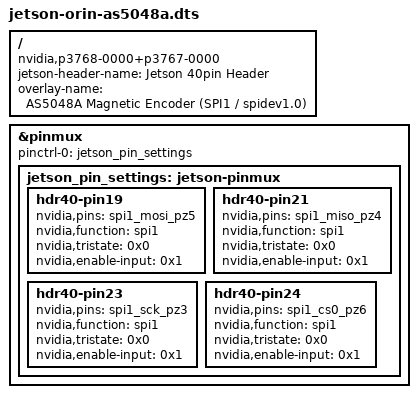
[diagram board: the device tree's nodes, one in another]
/dts-v1/;
/plugin/;

/ {
    jetson-header-name = "Jetson 40pin Header";
    overlay-name = "AS5048A Magnetic Encoder (SPI1 / spidev1.0)";
    compatible = "nvidia,p3768-0000+p3767-0000", "nvidia,p3768-0000+p3767-0001", "nvidia,p3768-0000+p3767-0003", "nvidia,p3768-0000+p3767-0004", "nvidia,p3768-0000+p3767-0005", "nvidia,p3768-0000+p3767-0000-super", "nvidia,p3768-0000+p3767-0001-super", "nvidia,p3768-0000+p3767-0003-super", "nvidia,p3768-0000+p3767-0004-super", "nvidia,p3768-0000+p3767-0005-super", "nvidia,p3509-0000+p3767-0000", "nvidia,p3509-0000+p3767-0001", "nvidia,p3509-0000+p3767-0003", "nvidia,p3509-0000+p3767-0004", "nvidia,p3509-0000+p3767-0005";

    /*
     * AS5048A magnetic rotary encoder, SPI mode 1, up to 10 MHz.
     * Uses Tegra SPI1 hardware block (spi@3230000) which Linux exposes
     * as /dev/spidev1.0 -- this is what the 40-pin header labels "SPI0".
     *
     *   Encoder pin   Jetson pin   Signal
     *   GND           25           GND
     *   3V3           17           3.3V
     *   MOSI          19           SPI1_MOSI (spi1_mosi_pz5)
     *   MISO          21           SPI1_MISO (spi1_miso_pz4)
     *   SCK           23           SPI1_SCK  (spi1_sck_pz3)
     *   CSN           24           SPI1_CS0  (spi1_cs0_pz6)
     *
     * No extra GPIO control pins -- CS is driven by the SPI controller.
     */
    fragment@0 {
        target = <&pinmux>;
        __overlay__ {
            pinctrl-names = "default";
            pinctrl-0 = <&jetson_pin_settings>;

            jetson_pin_settings: jetson-pinmux {

                /* SPI1 MOSI (Pin 19) */
                hdr40-pin19 {
                    nvidia,pins = "spi1_mosi_pz5";
                    nvidia,function = "spi1";
                    nvidia,tristate = <0x0>;
                    nvidia,enable-input = <0x1>;
                };

                /* SPI1 MISO (Pin 21) */
                hdr40-pin21 {
                    nvidia,pins = "spi1_miso_pz4";
                    nvidia,function = "spi1";
                    nvidia,tristate = <0x0>;
                    nvidia,enable-input = <0x1>;
                };

                /* SPI1 SCK (Pin 23) */
                hdr40-pin23 {
                    nvidia,pins = "spi1_sck_pz3";
                    nvidia,function = "spi1";
                    nvidia,tristate = <0x0>;
                    nvidia,enable-input = <0x1>;
                };

                /* SPI1 CS0 (Pin 24) -- AS5048A CSN */
                hdr40-pin24 {
                    nvidia,pins = "spi1_cs0_pz6";
                    nvidia,function = "spi1";
                    nvidia,tristate = <0x0>;
                    nvidia,enable-input = <0x1>;
                };
            };
        };
    };
};
